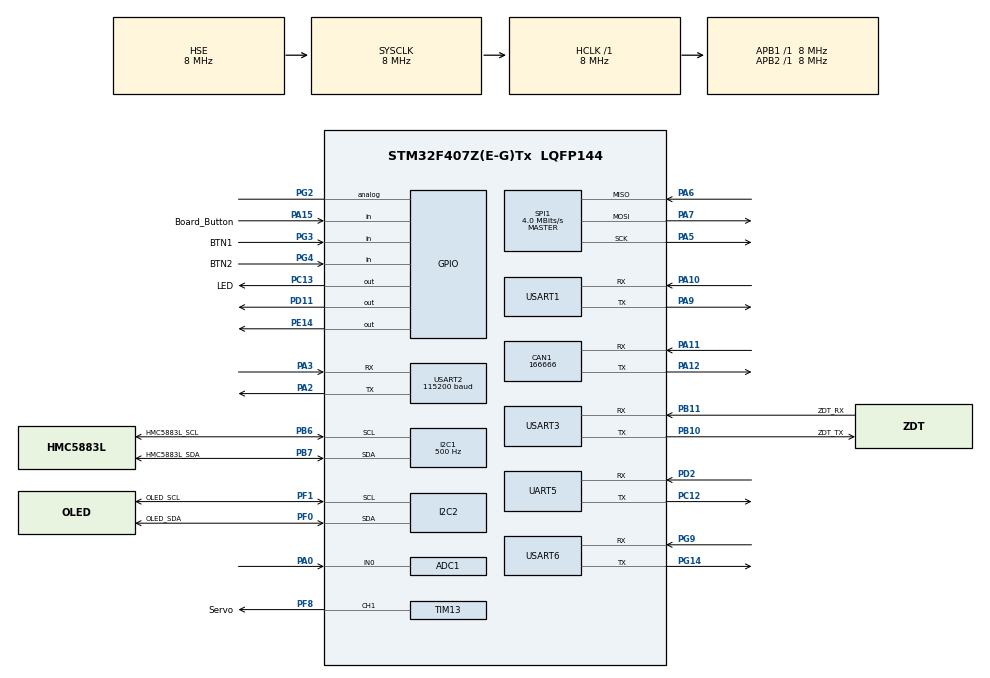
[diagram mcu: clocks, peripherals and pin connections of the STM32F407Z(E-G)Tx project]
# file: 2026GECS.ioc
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ADC1.Channel-1\#ChannelRegularConversion=ADC_CHANNEL_0
ADC1.NbrOfConversionFlag=1
ADC1.Rank-1\#ChannelRegularConversion=1
ADC1.SamplingTime-1\#ChannelRegularConversion=ADC_SAMPLETIME_3CYCLES
ADC1.master=1
CAN1.CalculateBaudRate=166666
CAN1.CalculateTimeBit=6000
CAN1.CalculateTimeQuantum=2000.0
Dma.Request0=USART6_RX
Dma.Request1=UART5_RX
Dma.Request2=USART2_RX
Dma.UART5_RX.1.Direction=DMA_PERIPH_TO_MEMORY
Dma.UART5_RX.1.FIFOMode=DMA_FIFOMODE_DISABLE
Dma.UART5_RX.1.Instance=DMA1_Stream0
Dma.UART5_RX.1.MemDataAlignment=DMA_MDATAALIGN_BYTE
Dma.UART5_RX.1.MemInc=DMA_MINC_ENABLE
Dma.UART5_RX.1.Mode=DMA_NORMAL
Dma.UART5_RX.1.PeriphDataAlignment=DMA_PDATAALIGN_BYTE
Dma.UART5_RX.1.PeriphInc=DMA_PINC_DISABLE
Dma.UART5_RX.1.Priority=DMA_PRIORITY_LOW
Dma.USART2_RX.2.Direction=DMA_PERIPH_TO_MEMORY
Dma.USART2_RX.2.FIFOMode=DMA_FIFOMODE_DISABLE
Dma.USART2_RX.2.Instance=DMA1_Stream5
Dma.USART2_RX.2.MemDataAlignment=DMA_MDATAALIGN_BYTE
Dma.USART2_RX.2.MemInc=DMA_MINC_ENABLE
Dma.USART2_RX.2.Mode=DMA_NORMAL
Dma.USART2_RX.2.PeriphDataAlignment=DMA_PDATAALIGN_BYTE
Dma.USART2_RX.2.PeriphInc=DMA_PINC_DISABLE
Dma.USART2_RX.2.Priority=DMA_PRIORITY_LOW
Dma.USART6_RX.0.Direction=DMA_PERIPH_TO_MEMORY
Dma.USART6_RX.0.FIFOMode=DMA_FIFOMODE_DISABLE
Dma.USART6_RX.0.Instance=DMA2_Stream1
Dma.USART6_RX.0.MemDataAlignment=DMA_MDATAALIGN_BYTE
Dma.USART6_RX.0.MemInc=DMA_MINC_ENABLE
Dma.USART6_RX.0.Mode=DMA_NORMAL
Dma.USART6_RX.0.PeriphDataAlignment=DMA_PDATAALIGN_BYTE
Dma.USART6_RX.0.PeriphInc=DMA_PINC_DISABLE
Dma.USART6_RX.0.Priority=DMA_PRIORITY_LOW
I2C1.ClockSpeed=500
I2C1.I2C_Mode=I2C_Standard
Mcu.Family=STM32F4
Mcu.Name=STM32F407Z(E-G)Tx
Mcu.Package=LQFP144
NVIC.DMA1_Stream0_IRQn=true\:0\:0\:false\:false\:true\:false\:true\:true
NVIC.DMA1_Stream5_IRQn=true\:0\:0\:false\:false\:true\:false\:true\:true
NVIC.DMA2_Stream1_IRQn=true\:0\:0\:false\:false\:true\:false\:true\:true
NVIC.PriorityGroup=NVIC_PRIORITYGROUP_4
NVIC.TIM1_UP_TIM10_IRQn=true\:0\:0\:false\:false\:true\:true\:true\:true
NVIC.TIM7_IRQn=true\:0\:0\:false\:false\:true\:true\:true\:true
NVIC.UART5_IRQn=true\:0\:0\:false\:false\:true\:true\:true\:true
NVIC.USART1_IRQn=true\:0\:0\:false\:false\:true\:true\:true\:true
NVIC.USART2_IRQn=true\:0\:0\:false\:false\:true\:true\:true\:true
NVIC.USART6_IRQn=true\:0\:0\:false\:false\:true\:true\:true\:true
PA0-WKUP.Signal=ADCx_IN0
PA10.Mode=Asynchronous
PA10.Signal=USART1_RX
PA11.Mode=CAN_Activate
PA11.Signal=CAN1_RX
PA12.Mode=CAN_Activate
PA12.Signal=CAN1_TX
PA15.GPIO_Label=Board_Button
PA15.Signal=GPIO_Input
PA2.Mode=Asynchronous
PA2.Signal=USART2_TX
PA3.Mode=Asynchronous
PA3.Signal=USART2_RX
PA5.Mode=Full_Duplex_Master
PA5.Signal=SPI1_SCK
PA6.Mode=Full_Duplex_Master
PA6.Signal=SPI1_MISO
PA7.Mode=Full_Duplex_Master
PA7.Signal=SPI1_MOSI
PA9.Mode=Asynchronous
PA9.Signal=USART1_TX
PB10.GPIO_Label=ZDT_TX
PB10.Mode=Asynchronous
PB10.Signal=USART3_TX
PB11.GPIO_Label=ZDT_RX
PB11.Mode=Asynchronous
PB11.Signal=USART3_RX
PB6.GPIO_Label=HMC5883L_SCL
PB6.GPIO_Pu=GPIO_NOPULL
PB6.Mode=I2C
PB6.Signal=I2C1_SCL
PB7.GPIO_Label=HMC5883L_SDA
PB7.GPIO_Pu=GPIO_NOPULL
PB7.Mode=I2C
PB7.Signal=I2C1_SDA
PC12.Mode=Asynchronous
PC12.Signal=UART5_TX
PC13-ANTI_TAMP.GPIO_Label=LED
PC13-ANTI_TAMP.PinState=GPIO_PIN_SET
PC13-ANTI_TAMP.Signal=GPIO_Output
PD11.GPIO_PuPd=GPIO_PULLUP
PD11.PinState=GPIO_PIN_RESET
PD11.Signal=GPIO_Output
PD2.Mode=Asynchronous
PD2.Signal=UART5_RX
PE14.Signal=GPIO_Output
PF0.GPIO_Label=OLED_SDA
PF0.Mode=I2C
PF0.Signal=I2C2_SDA
PF1.GPIO_Label=OLED_SCL
PF1.Mode=I2C
PF1.Signal=I2C2_SCL
PF8.GPIO_Label=Servo
PF8.Signal=S_TIM13_CH1
PG14.Mode=Asynchronous
PG14.Signal=USART6_TX
PG2.Signal=GPIO_Analog
PG3.GPIO_Label=BTN1
PG3.GPIO_PuPd=GPIO_PULLUP
PG3.Signal=GPIO_Input
PG4.GPIO_Label=BTN2
PG4.GPIO_PuPd=GPIO_PULLUP
PG4.Signal=GPIO_Input
PG9.Mode=Asynchronous
PG9.Signal=USART6_RX
PH0-OSC_IN.Mode=HSE-External-Oscillator
PH0-OSC_IN.Signal=RCC_OSC_IN
PH1-OSC_OUT.Mode=HSE-External-Oscillator
PH1-OSC_OUT.Signal=RCC_OSC_OUT
ProjectManager.HeapSize=0x200
ProjectManager.StackSize=0x400
ProjectManager.TargetToolchain=MDK-ARM V5.32
RCC.48MHZClocksFreq_Value=48000000
RCC.AHBFreq_Value=8000000
RCC.APB1Freq_Value=8000000
RCC.APB1TimFreq_Value=8000000
RCC.APB2Freq_Value=8000000
RCC.APB2TimFreq_Value=8000000
RCC.CortexFreq_Value=8000000
RCC.HCLKFreq_Value=8000000
RCC.HSE_VALUE=8000000
RCC.HSI_VALUE=16000000
RCC.LSE_VALUE=32768
RCC.SYSCLKFreq_VALUE=8000000
RCC.SYSCLKSource=RCC_SYSCLKSOURCE_HSE
RCC.VCOOutputFreq_Value=192000000
SH.ADCx_IN0.0=ADC1_IN0,IN0
SH.S_TIM13_CH1.0=TIM13_CH1,PWM Generation1 CH1
SPI1.BaudRatePrescaler=SPI_BAUDRATEPRESCALER_2
SPI1.CalculateBaudRate=4.0 MBits/s
SPI1.Direction=SPI_DIRECTION_2LINES
SPI1.Mode=SPI_MODE_MASTER
SPI1.VirtualType=VM_MASTER
TIM10.AutoReloadPreload=TIM_AUTORELOAD_PRELOAD_ENABLE
TIM10.Period=99
TIM10.Prescaler=799
TIM13.AutoReloadPreload=TIM_AUTORELOAD_PRELOAD_ENABLE
TIM13.Channel=TIM_CHANNEL_1
TIM13.OCPolarity_1=TIM_OCPOLARITY_LOW
TIM13.Period=19999
TIM13.Prescaler=7
TIM7.Period=99
TIM7.Prescaler=7999
UART5.VirtualMode=Asynchronous
USART1.VirtualMode=VM_ASYNC
USART2.BaudRate=115200
USART2.VirtualMode=VM_ASYNC
USART3.VirtualMode=VM_ASYNC
USART6.VirtualMode=VM_ASYNC
VP_TIM10_VS_ClockSourceINT.Mode=Enable_Timer
VP_TIM13_VS_ClockSourceINT.Mode=Enable_Timer
VP_TIM7_VS_ClockSourceINT.Mode=Enable_Timer
board=custom

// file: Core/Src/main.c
/* USER CODE BEGIN Header */
/**
  ******************************************************************************
  * @file           : main.c
  * @brief          : Main program body
  ******************************************************************************
  * @attention
  *
  * Copyright (c) 2026 STMicroelectronics.
  * All rights reserved.
  *
  * This software is licensed under terms that can be found in the LICENSE file
  * in the root directory of this software component.
  * If no LICENSE file comes with this software, it is provided AS-IS.
  *
  ******************************************************************************
  */
/* USER CODE END Header */
#include "main.h"

/* USER CODE BEGIN Includes */
#include "App.h"
/* USER CODE END Includes */

ADC_HandleTypeDef hadc1;

CAN_HandleTypeDef hcan1;

I2C_HandleTypeDef hi2c1;
I2C_HandleTypeDef hi2c2;

SPI_HandleTypeDef hspi1;

TIM_HandleTypeDef htim7;
TIM_HandleTypeDef htim10;
TIM_HandleTypeDef htim13;

UART_HandleTypeDef huart5;
UART_HandleTypeDef huart1;
UART_HandleTypeDef huart2;
UART_HandleTypeDef huart3;
UART_HandleTypeDef huart6;
DMA_HandleTypeDef hdma_uart5_rx;
DMA_HandleTypeDef hdma_usart2_rx;
DMA_HandleTypeDef hdma_usart6_rx;

void SystemClock_Config(void);
static void MX_GPIO_Init(void);
static void MX_DMA_Init(void);
static void MX_ADC1_Init(void);
static void MX_I2C1_Init(void);
static void MX_SPI1_Init(void);
static void MX_USART2_UART_Init(void);
static void MX_TIM13_Init(void);
static void MX_USART3_UART_Init(void);
static void MX_I2C2_Init(void);
static void MX_UART5_Init(void);
static void MX_USART1_UART_Init(void);
static void MX_USART6_UART_Init(void);
static void MX_CAN1_Init(void);
static void MX_TIM7_Init(void);
static void MX_TIM10_Init(void);

int main(void)
{

	/* MCU Configuration--------------------------------------------------------*/

	/* Reset of all peripherals, Initializes the Flash interface and the Systick. */
	HAL_Init();

	/* Configure the system clock */
	SystemClock_Config();

	/* Initialize all configured peripherals */
	MX_GPIO_Init();
	MX_DMA_Init();
	MX_ADC1_Init();
	MX_I2C1_Init();
	MX_SPI1_Init();
	MX_USART2_UART_Init();
	MX_TIM13_Init();
	MX_USART3_UART_Init();
	MX_I2C2_Init();
	MX_UART5_Init();
	MX_USART1_UART_Init();
	MX_USART6_UART_Init();
	MX_CAN1_Init();
	MX_TIM7_Init();
	MX_TIM10_Init();
  /* USER CODE BEGIN 2 */
	App_Init();
  /* USER CODE END 2 */

	/* Infinite loop */
	while (1)
	{

		/* USER CODE BEGIN 3 */
		App_Run();
	}
	/* USER CODE END 3 */
}

void SystemClock_Config(void)
{
	RCC_OscInitTypeDef RCC_OscInitStruct = {0};
	RCC_ClkInitTypeDef RCC_ClkInitStruct = {0};

	/** Configure the main internal regulator output voltage
	*/
	__HAL_RCC_PWR_CLK_ENABLE();
	__HAL_PWR_VOLTAGESCALING_CONFIG(PWR_REGULATOR_VOLTAGE_SCALE1);

	/** Initializes the RCC Oscillators according to the specified parameters
	* in the RCC_OscInitTypeDef structure.
	*/
	RCC_OscInitStruct.OscillatorType = RCC_OSCILLATORTYPE_HSE;
	RCC_OscInitStruct.HSEState = RCC_HSE_ON;
	RCC_OscInitStruct.PLL.PLLState = RCC_PLL_NONE;
	if (HAL_RCC_OscConfig(&RCC_OscInitStruct) != HAL_OK)
	{
		Error_Handler();
	}

	/** Initializes the CPU, AHB and APB buses clocks
	*/
	RCC_ClkInitStruct.ClockType = RCC_CLOCKTYPE_HCLK|RCC_CLOCKTYPE_SYSCLK
															|RCC_CLOCKTYPE_PCLK1|RCC_CLOCKTYPE_PCLK2;
	RCC_ClkInitStruct.SYSCLKSource = RCC_SYSCLKSOURCE_HSE;
	RCC_ClkInitStruct.AHBCLKDivider = RCC_SYSCLK_DIV1;
	RCC_ClkInitStruct.APB1CLKDivider = RCC_HCLK_DIV1;
	RCC_ClkInitStruct.APB2CLKDivider = RCC_HCLK_DIV1;

	if (HAL_RCC_ClockConfig(&RCC_ClkInitStruct, FLASH_LATENCY_0) != HAL_OK)
	{
		Error_Handler();
	}
}

static void MX_ADC1_Init(void)
{

	ADC_ChannelConfTypeDef sConfig = {0};

	/** Configure the global features of the ADC (Clock, Resolution, Data Alignment and number of conversion)
	*/
	hadc1.Instance = ADC1;
	hadc1.Init.ClockPrescaler = ADC_CLOCK_SYNC_PCLK_DIV2;
	hadc1.Init.Resolution = ADC_RESOLUTION_12B;
	hadc1.Init.ScanConvMode = DISABLE;
	hadc1.Init.ContinuousConvMode = DISABLE;
	hadc1.Init.DiscontinuousConvMode = DISABLE;
	hadc1.Init.ExternalTrigConvEdge = ADC_EXTERNALTRIGCONVEDGE_NONE;
	hadc1.Init.ExternalTrigConv = ADC_SOFTWARE_START;
	hadc1.Init.DataAlign = ADC_DATAALIGN_RIGHT;
	hadc1.Init.NbrOfConversion = 1;
	hadc1.Init.DMAContinuousRequests = DISABLE;
	hadc1.Init.EOCSelection = ADC_EOC_SINGLE_CONV;
	if (HAL_ADC_Init(&hadc1) != HAL_OK)
	{
		Error_Handler();
	}

	/** Configure for the selected ADC regular channel its corresponding rank in the sequencer and its sample time.
	*/
	sConfig.Channel = ADC_CHANNEL_0;
	sConfig.Rank = 1;
	sConfig.SamplingTime = ADC_SAMPLETIME_3CYCLES;
	if (HAL_ADC_ConfigChannel(&hadc1, &sConfig) != HAL_OK)
	{
		Error_Handler();
	}

}

static void MX_CAN1_Init(void)
{

	hcan1.Instance = CAN1;
	hcan1.Init.Prescaler = 16;
	hcan1.Init.Mode = CAN_MODE_NORMAL;
	hcan1.Init.SyncJumpWidth = CAN_SJW_1TQ;
	hcan1.Init.TimeSeg1 = CAN_BS1_1TQ;
	hcan1.Init.TimeSeg2 = CAN_BS2_1TQ;
	hcan1.Init.TimeTriggeredMode = DISABLE;
	hcan1.Init.AutoBusOff = DISABLE;
	hcan1.Init.AutoWakeUp = DISABLE;
	hcan1.Init.AutoRetransmission = DISABLE;
	hcan1.Init.ReceiveFifoLocked = DISABLE;
	hcan1.Init.TransmitFifoPriority = DISABLE;
	if (HAL_CAN_Init(&hcan1) != HAL_OK)
	{
		Error_Handler();
	}

}

static void MX_I2C1_Init(void)
{

	hi2c1.Instance = I2C1;
	hi2c1.Init.ClockSpeed = 500;
	hi2c1.Init.DutyCycle = I2C_DUTYCYCLE_2;
	hi2c1.Init.OwnAddress1 = 0;
	hi2c1.Init.AddressingMode = I2C_ADDRESSINGMODE_7BIT;
	hi2c1.Init.DualAddressMode = I2C_DUALADDRESS_DISABLE;
	hi2c1.Init.OwnAddress2 = 0;
	hi2c1.Init.GeneralCallMode = I2C_GENERALCALL_DISABLE;
	hi2c1.Init.NoStretchMode = I2C_NOSTRETCH_DISABLE;
	if (HAL_I2C_Init(&hi2c1) != HAL_OK)
	{
		Error_Handler();
	}

}

static void MX_I2C2_Init(void)
{

	hi2c2.Instance = I2C2;
	hi2c2.Init.ClockSpeed = 100000;
	hi2c2.Init.DutyCycle = I2C_DUTYCYCLE_2;
	hi2c2.Init.OwnAddress1 = 0;
	hi2c2.Init.AddressingMode = I2C_ADDRESSINGMODE_7BIT;
	hi2c2.Init.DualAddressMode = I2C_DUALADDRESS_DISABLE;
	hi2c2.Init.OwnAddress2 = 0;
	hi2c2.Init.GeneralCallMode = I2C_GENERALCALL_DISABLE;
	hi2c2.Init.NoStretchMode = I2C_NOSTRETCH_DISABLE;
	if (HAL_I2C_Init(&hi2c2) != HAL_OK)
	{
		Error_Handler();
	}

}

static void MX_SPI1_Init(void)
{

	/* SPI1 parameter configuration*/
	hspi1.Instance = SPI1;
	hspi1.Init.Mode = SPI_MODE_MASTER;
	hspi1.Init.Direction = SPI_DIRECTION_2LINES;
	hspi1.Init.DataSize = SPI_DATASIZE_8BIT;
	hspi1.Init.CLKPolarity = SPI_POLARITY_LOW;
	hspi1.Init.CLKPhase = SPI_PHASE_1EDGE;
	hspi1.Init.NSS = SPI_NSS_SOFT;
	hspi1.Init.BaudRatePrescaler = SPI_BAUDRATEPRESCALER_2;
	hspi1.Init.FirstBit = SPI_FIRSTBIT_MSB;
	hspi1.Init.TIMode = SPI_TIMODE_DISABLE;
	hspi1.Init.CRCCalculation = SPI_CRCCALCULATION_DISABLE;
	hspi1.Init.CRCPolynomial = 10;
	if (HAL_SPI_Init(&hspi1) != HAL_OK)
	{
		Error_Handler();
	}

}

static void MX_TIM7_Init(void)
{

	TIM_MasterConfigTypeDef sMasterConfig = {0};

	htim7.Instance = TIM7;
	htim7.Init.Prescaler = 7999;
	htim7.Init.CounterMode = TIM_COUNTERMODE_UP;
	htim7.Init.Period = 99;
	htim7.Init.AutoReloadPreload = TIM_AUTORELOAD_PRELOAD_DISABLE;
	if (HAL_TIM_Base_Init(&htim7) != HAL_OK)
	{
		Error_Handler();
	}
	sMasterConfig.MasterOutputTrigger = TIM_TRGO_RESET;
	sMasterConfig.MasterSlaveMode = TIM_MASTERSLAVEMODE_DISABLE;
	if (HAL_TIMEx_MasterConfigSynchronization(&htim7, &sMasterConfig) != HAL_OK)
	{
		Error_Handler();
	}

}

static void MX_TIM10_Init(void)
{

	htim10.Instance = TIM10;
	htim10.Init.Prescaler = 799;
	htim10.Init.CounterMode = TIM_COUNTERMODE_UP;
	htim10.Init.Period = 99;
	htim10.Init.ClockDivision = TIM_CLOCKDIVISION_DIV1;
	htim10.Init.AutoReloadPreload = TIM_AUTORELOAD_PRELOAD_ENABLE;
	if (HAL_TIM_Base_Init(&htim10) != HAL_OK)
	{
		Error_Handler();
	}

}

static void MX_TIM13_Init(void)
{

	TIM_OC_InitTypeDef sConfigOC = {0};

	htim13.Instance = TIM13;
	htim13.Init.Prescaler = 7;
	htim13.Init.CounterMode = TIM_COUNTERMODE_UP;
	htim13.Init.Period = 19999;
	htim13.Init.ClockDivision = TIM_CLOCKDIVISION_DIV1;
	htim13.Init.AutoReloadPreload = TIM_AUTORELOAD_PRELOAD_ENABLE;
	if (HAL_TIM_Base_Init(&htim13) != HAL_OK)
	{
		Error_Handler();
	}
	if (HAL_TIM_PWM_Init(&htim13) != HAL_OK)
	{
		Error_Handler();
	}
	sConfigOC.OCMode = TIM_OCMODE_PWM1;
	sConfigOC.Pulse = 0;
	sConfigOC.OCPolarity = TIM_OCPOLARITY_LOW;
	sConfigOC.OCFastMode = TIM_OCFAST_DISABLE;
	if (HAL_TIM_PWM_ConfigChannel(&htim13, &sConfigOC, TIM_CHANNEL_1) != HAL_OK)
	{
		Error_Handler();
	}
	HAL_TIM_MspPostInit(&htim13);

}

static void MX_UART5_Init(void)
{

	huart5.Instance = UART5;
	huart5.Init.BaudRate = 115200;
	huart5.Init.WordLength = UART_WORDLENGTH_8B;
	huart5.Init.StopBits = UART_STOPBITS_1;
	huart5.Init.Parity = UART_PARITY_NONE;
	huart5.Init.Mode = UART_MODE_TX_RX;
	huart5.Init.HwFlowCtl = UART_HWCONTROL_NONE;
	huart5.Init.OverSampling = UART_OVERSAMPLING_16;
	if (HAL_UART_Init(&huart5) != HAL_OK)
	{
		Error_Handler();
	}

}

static void MX_USART1_UART_Init(void)
{

	huart1.Instance = USART1;
	huart1.Init.BaudRate = 115200;
	huart1.Init.WordLength = UART_WORDLENGTH_8B;
	huart1.Init.StopBits = UART_STOPBITS_1;
	huart1.Init.Parity = UART_PARITY_NONE;
	huart1.Init.Mode = UART_MODE_TX_RX;
	huart1.Init.HwFlowCtl = UART_HWCONTROL_NONE;
	huart1.Init.OverSampling = UART_OVERSAMPLING_16;
	if (HAL_UART_Init(&huart1) != HAL_OK)
	{
		Error_Handler();
	}

}

static void MX_USART2_UART_Init(void)
{

	huart2.Instance = USART2;
	huart2.Init.BaudRate = 115200;
	huart2.Init.WordLength = UART_WORDLENGTH_8B;
	huart2.Init.StopBits = UART_STOPBITS_1;
	huart2.Init.Parity = UART_PARITY_NONE;
	huart2.Init.Mode = UART_MODE_TX_RX;
	huart2.Init.HwFlowCtl = UART_HWCONTROL_NONE;
	huart2.Init.OverSampling = UART_OVERSAMPLING_16;
	if (HAL_UART_Init(&huart2) != HAL_OK)
	{
		Error_Handler();
	}

}

static void MX_USART3_UART_Init(void)
{

	huart3.Instance = USART3;
	huart3.Init.BaudRate = 115200;
	huart3.Init.WordLength = UART_WORDLENGTH_8B;
	huart3.Init.StopBits = UART_STOPBITS_1;
	huart3.Init.Parity = UART_PARITY_NONE;
	huart3.Init.Mode = UART_MODE_TX_RX;
	huart3.Init.HwFlowCtl = UART_HWCONTROL_NONE;
	huart3.Init.OverSampling = UART_OVERSAMPLING_16;
	if (HAL_UART_Init(&huart3) != HAL_OK)
	{
		Error_Handler();
	}

}

static void MX_USART6_UART_Init(void)
{

	huart6.Instance = USART6;
	huart6.Init.BaudRate = 115200;
	huart6.Init.WordLength = UART_WORDLENGTH_8B;
	huart6.Init.StopBits = UART_STOPBITS_1;
	huart6.Init.Parity = UART_PARITY_NONE;
	huart6.Init.Mode = UART_MODE_TX_RX;
	huart6.Init.HwFlowCtl = UART_HWCONTROL_NONE;
	huart6.Init.OverSampling = UART_OVERSAMPLING_16;
	if (HAL_UART_Init(&huart6) != HAL_OK)
	{
		Error_Handler();
	}

}

static void MX_DMA_Init(void)
{

  /* DMA controller clock enable */
  __HAL_RCC_DMA2_CLK_ENABLE();
  __HAL_RCC_DMA1_CLK_ENABLE();

	/* DMA interrupt init */
	/* DMA1_Stream0_IRQn interrupt configuration */
	HAL_NVIC_SetPriority(DMA1_Stream0_IRQn, 0, 0);
	HAL_NVIC_EnableIRQ(DMA1_Stream0_IRQn);
	/* DMA1_Stream5_IRQn interrupt configuration */
	HAL_NVIC_SetPriority(DMA1_Stream5_IRQn, 0, 0);
	HAL_NVIC_EnableIRQ(DMA1_Stream5_IRQn);
	/* DMA2_Stream1_IRQn interrupt configuration */
	HAL_NVIC_SetPriority(DMA2_Stream1_IRQn, 0, 0);
	HAL_NVIC_EnableIRQ(DMA2_Stream1_IRQn);

}

static void MX_GPIO_Init(void)
{
	GPIO_InitTypeDef GPIO_InitStruct = {0};

	/* GPIO Ports Clock Enable */
	__HAL_RCC_GPIOC_CLK_ENABLE();
	__HAL_RCC_GPIOF_CLK_ENABLE();
	__HAL_RCC_GPIOH_CLK_ENABLE();
	__HAL_RCC_GPIOA_CLK_ENABLE();
	__HAL_RCC_GPIOE_CLK_ENABLE();
	__HAL_RCC_GPIOB_CLK_ENABLE();
	__HAL_RCC_GPIOD_CLK_ENABLE();
	__HAL_RCC_GPIOG_CLK_ENABLE();

	/*Configure GPIO pin Output Level */
	HAL_GPIO_WritePin(LED_GPIO_Port, LED_Pin, GPIO_PIN_SET);

	/*Configure GPIO pin Output Level */
	HAL_GPIO_WritePin(GPIOE, GPIO_PIN_14, GPIO_PIN_RESET);

	/*Configure GPIO pin Output Level */
	HAL_GPIO_WritePin(GPIOD, GPIO_PIN_11, GPIO_PIN_RESET);

	/*Configure GPIO pin : LED_Pin */
	GPIO_InitStruct.Pin = LED_Pin;
	GPIO_InitStruct.Mode = GPIO_MODE_OUTPUT_PP;
	GPIO_InitStruct.Pull = GPIO_NOPULL;
	GPIO_InitStruct.Speed = GPIO_SPEED_FREQ_LOW;
	HAL_GPIO_Init(LED_GPIO_Port, &GPIO_InitStruct);

	/*Configure GPIO pin : PE14 */
	GPIO_InitStruct.Pin = GPIO_PIN_14;
	GPIO_InitStruct.Mode = GPIO_MODE_OUTPUT_PP;
	GPIO_InitStruct.Pull = GPIO_NOPULL;
	GPIO_InitStruct.Speed = GPIO_SPEED_FREQ_LOW;
	HAL_GPIO_Init(GPIOE, &GPIO_InitStruct);

	/*Configure GPIO pin : PD11 */
	GPIO_InitStruct.Pin = GPIO_PIN_11;
	GPIO_InitStruct.Mode = GPIO_MODE_OUTPUT_PP;
	GPIO_InitStruct.Pull = GPIO_PULLUP;
	GPIO_InitStruct.Speed = GPIO_SPEED_FREQ_LOW;
	HAL_GPIO_Init(GPIOD, &GPIO_InitStruct);

	/*Configure GPIO pin : PG2 */
	GPIO_InitStruct.Pin = GPIO_PIN_2;
	GPIO_InitStruct.Mode = GPIO_MODE_ANALOG;
	GPIO_InitStruct.Pull = GPIO_NOPULL;
	HAL_GPIO_Init(GPIOG, &GPIO_InitStruct);

	/*Configure GPIO pins : BTN1_Pin BTN2_Pin */
	GPIO_InitStruct.Pin = BTN1_Pin|BTN2_Pin;
	GPIO_InitStruct.Mode = GPIO_MODE_INPUT;
	GPIO_InitStruct.Pull = GPIO_PULLUP;
	HAL_GPIO_Init(GPIOG, &GPIO_InitStruct);

	/*Configure GPIO pin : Board_Button_Pin */
	GPIO_InitStruct.Pin = Board_Button_Pin;
	GPIO_InitStruct.Mode = GPIO_MODE_INPUT;
	GPIO_InitStruct.Pull = GPIO_NOPULL;
	HAL_GPIO_Init(Board_Button_GPIO_Port, &GPIO_InitStruct);

}

void Error_Handler(void)
{
  __disable_irq();
  while (1)
  {
  }
}
